VERSION "Body_CAN_v1.0"

NS_ :

BS_:

BU_: BODY_GW BCM_AMBIENT_CTRL HAZARD_CTRL WINDOW_CTRL DRIVER_STATE_CTRL WARN_ARB_MGR Vector__XXX

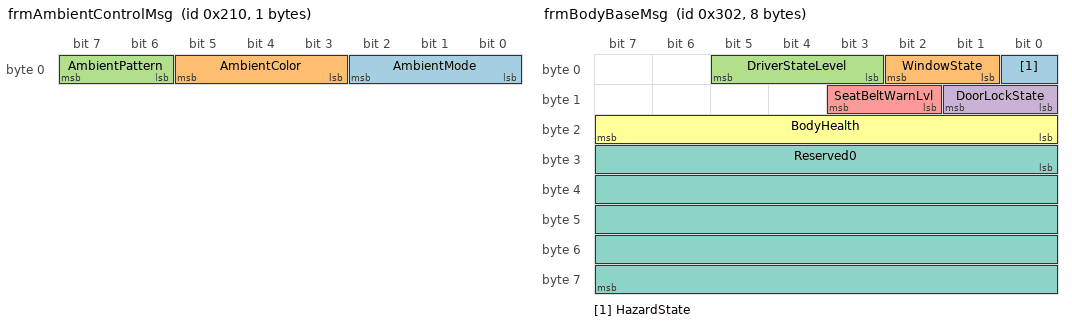
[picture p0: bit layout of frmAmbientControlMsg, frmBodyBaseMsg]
BO_ 528 frmAmbientControlMsg: 1 BODY_GW
 SG_ AmbientMode    : 0|3@1+ (1,0) [0|7] "" BCM_AMBIENT_CTRL
 SG_ AmbientColor   : 3|3@1+ (1,0) [0|7] "" BCM_AMBIENT_CTRL
 SG_ AmbientPattern : 6|2@1+ (1,0) [0|3] "" BCM_AMBIENT_CTRL

BO_ 770 frmBodyBaseMsg: 8 BODY_GW
 SG_ HazardState      : 0|1@1+ (1,0) [0|1] "" HAZARD_CTRL
 SG_ WindowState      : 1|2@1+ (1,0) [0|3] "" WINDOW_CTRL
 SG_ DriverStateLevel : 3|3@1+ (1,0) [0|7] "" DRIVER_STATE_CTRL
 SG_ DoorLockState    : 8|2@1+ (1,0) [0|3] "" WINDOW_CTRL
 SG_ SeatBeltWarnLvl  : 10|2@1+ (1,0) [0|3] "" DRIVER_STATE_CTRL
 SG_ BodyHealth       : 16|8@1+ (1,0) [0|255] "" WARN_ARB_MGR
 SG_ Reserved0        : 24|40@1+ (1,0) [0|0] "" Vector__XXX

CM_ BO_ 528 "Flow_007 ambient output.";
CM_ BO_ 770 "Comm_103 baseline body aggregate message (Req_106~Req_108).";

BA_DEF_ BO_ "GenMsgCycleTime" INT 0 10000;
BA_DEF_DEF_ "GenMsgCycleTime" 0;
BA_ "GenMsgCycleTime" BO_ 528 50;
BA_ "GenMsgCycleTime" BO_ 770 100;

  0 "Off"
  1 "Basic"
  2 "Caution"
  3 "SchoolZone"
  4 "Reserved"
  5 "GuideLeft"
  6 "GuideRight"
  7 "Emergency" ;
